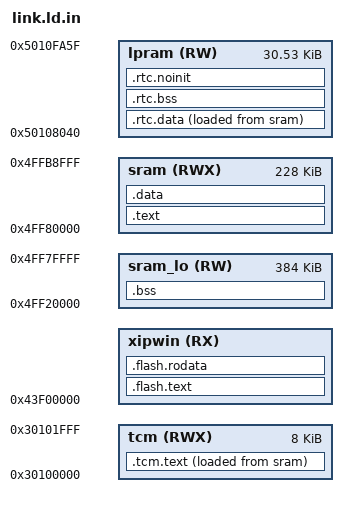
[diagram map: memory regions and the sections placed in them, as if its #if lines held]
/* ESP32-P4 (v3.x) image, run through the C preprocessor (NDF_* from the Makefile).
 * HP L2MEM 0x4FF00000-0x4FFC0000 (768 KB) is one RWX space for code and data. Its low end is the L2 cache (size set at
 * boot, up to 512 KB while the ROM runs) and the ROM's own data starts at 0x4FFBCFC0 (IDF bootloader.memory.ld.in,
 * bootloader_usable_dram_end for v3), so everything the ROM loads (code, data) goes into ROM_LO..ROM_HI. .bss and the
 * stacks go below it, into 0x4FF20000..ROM_LO, which becomes plain memory once sys_start0 has set the L2 cache to
 * 128 KB (cache.c) - before anything touches .bss or the stacks. Heap: the rest of both.
 * ponytail: TCM 0x30100000 (8 KB, zero wait) is unused; move irq_entry there (copied at boot, esptool must not see it
 * as a load segment) once the board shows L2 fetch latency in irq_latency. */
#ifndef NDF_ULP_RESERVE
#define NDF_ULP_RESERVE 0     /* bytes of LP RAM from 0x50108000 for an LP core program (ulp.h); two note words follow it */
#endif
#define XIP_VWIN 0x3F00000         /* code window: 1 MB at 0x43F00000 (flash MMU entries 1008-1023, cache.c) */
#define ROM_LO  0x4FF80000
#if NDF_BOOT_LOAD_ADDR                 /* BOOT_FAST: the ROM loads loader/loader.c, which copies the app (OTA slots); the loader keeps the top */
#define ROM_HI  0x4FFB9000               /* SOC_LOADER_BASE (soc_caps.h) */
#else
#define ROM_HI  0x4FFBCFC0
#endif
#define L2_FREE_LO 0x4FF20000      /* above a 128 KB L2 cache */
ENTRY(_start0)

MEMORY
{
    sram (RWX) : ORIGIN = ROM_LO, LENGTH = ROM_HI - ROM_LO
    sram_lo (RW) : ORIGIN = L2_FREE_LO, LENGTH = ROM_LO - L2_FREE_LO   /* not loaded by the ROM: zeroed / used after boot */
    xipwin (RX) : ORIGIN = 0x40000000 + XIP_VWIN, LENGTH = NDF_XIP_SIZE   /* code, then read-only data, in flash through the caches */
    tcm (RWX) : ORIGIN = 0x30100000, LENGTH = 0x2000   /* HP TCM: irq_entry with NDF_TCM_IRQ; not loaded by the ROM, copied at boot (sys.c) */
    lpram (RW) : ORIGIN = 0x50108000 + NDF_ULP_RESERVE + 0x40, LENGTH = 0x7A60 - NDF_ULP_RESERVE - 0x40   /* LP RAM below the loader note (0x5010FA60) and the LP ROM data (0x5010FA80); first 64 B: notes */
}

/* Same split as the S3 (esp32s3/link.ld.in): libraries never called from interrupts, flash operations or the panic
 * path. "*build*" because the P4 objects are in build-esp32p4/. */
#define XIP_LIB(S) *build*?ndf?components?lib?strtod.c.o(S) *build*?ndf?components?lib?bigint.c.o(S) *build*?ndf?components?lib?stdlib.c.o(S) *build*?ndf?components?lib?math.c.o(S) *build*?ndf?components?lib?mathf.c.o(S) \
                   *build*?ndf?components?lib?double.c.o(S) *build*?ndf?components?lib?md5.c.o(S) *build*?ndf?components?lib?crc32.c.o(S) *build*?ndf?components?lib?p256_comb.c.o(S) *build*?ndf?components?lib?ecc.c.o(S) *build*?ndf?components?lib?musl?*.c.o(S)
#define XIP_ALL(S) *build*?app?*.o(S) *build*?ndf?components?drivers?storage?*.o(S)

SECTIONS
{
#if NDF_XIP
    .flash.text : {
        _flash_text_start = ABSOLUTE(.);
        *(.flash.text .flash.text.*)                       /* FLASH_FN */
        XIP_LIB(.text .text.*)
#if NDF_XIP == 2
        XIP_ALL(.text .text.*)
#endif
        . = ALIGN(16);
        _flash_text_end = ABSOLUTE(.);
    } > xipwin

    .flash.rodata ORIGIN(xipwin) + SIZEOF(.flash.text) : {   /* same flash offset as the end of the code */
        _flash_rodata_start = ABSOLUTE(.);
        XIP_LIB(.rodata .rodata.*)
#if NDF_XIP == 2
        XIP_ALL(.rodata .rodata.*)
#endif
        . = ALIGN(16);
        _flash_rodata_end = ABSOLUTE(.);
    } > xipwin
#else
    _flash_text_start = 0; _flash_text_end = 0;
#endif

    .text : {
        KEEP(*(.iram.text .iram.text.*))            /* entry and _trap_vec (64-byte aligned) */
        *(.text .text.*)
        . = ALIGN(128);                             /* PMP granule: the code / data split of memprot.c */
        _text_end = .;
    } > sram

    .data : {
        *(.rodata .rodata.* .srodata .srodata.*)
        . = ALIGN(4);
        __global_pointer$ = . + 0x800;
        *(.data .data.* .sdata .sdata.*)
        . = ALIGN(4);
        __init_array_start = .;
        KEEP(*(SORT_BY_INIT_PRIORITY(.init_array.*) SORT_BY_INIT_PRIORITY(.ctors.*)))
        KEEP(*(.init_array .ctors))
        __init_array_end = .;
        . = ALIGN(4);
        __cmd_start = .;  KEEP(*(SORT_BY_NAME(.ndf_reg.cmd.*)))  __cmd_end = .;    /* cmd.h */
        __test_start = .; KEEP(*(SORT(.ndf_reg.test.*)))         __test_end = .;   /* unit.h, by name */
        _data_end = .;
    } > sram

    /* .tcm.text: runs in TCM, stored after .data (AT > sram), copied by sys_start0 before interrupts are enabled */
    .tcm.text : { _tcm_start = .; KEEP(*(.tcm.text .tcm.text.*)) . = ALIGN(4); _tcm_end = .; } > tcm AT > sram
    _tcm_load = LOADADDR(.tcm.text);

    .bss (NOLOAD) : ALIGN(16) {
        _bss_start = .;
        *(.sbss .sbss.* .bss .bss.* COMMON)
        . = ALIGN(4);
        _bss_end = .;
        . = ALIGN(16); _stack0_bot = .; . += NDF_STACK0_SIZE; _stack0_top = .;
        . = ALIGN(16); _stack1_bot = .; . += NDF_STACK1_SIZE; _stack1_top = .;
    } > sram_lo
    _heap_start = LOADADDR(.rtc.data) + SIZEOF(.rtc.data);
    _heap_end = ROM_HI;
    _heap2_start = _stack1_top;
    _heap2_end = ROM_LO;

    /* RTC_DATA_ATTR: lives in LP RAM (kept through deep sleep); the ROM only loads L2MEM, so the initial values travel in the
     * image after .data (AT > sram) and sys_start0 copies them on every power-up / reset except a deep-sleep wake */
    .rtc.data : { _rtc_data_start = .; *(.rtc.data .rtc.data.*) . = ALIGN(4); _rtc_data_end = .; } > lpram AT > sram
    _rtc_data_load = LOADADDR(.rtc.data);
    .rtc.bss (NOLOAD) : { _rtc_bss_start = .; *(.rtc.bss .rtc.bss.*) . = ALIGN(4); _rtc_bss_end = .; } > lpram
    .rtc.noinit (NOLOAD) : { *(.rtc.noinit .rtc.noinit.*) } > lpram

    /DISCARD/ : { *(.comment .note.* .eh_frame .riscv.attributes) }
}

ASSERT(_trap_vec % 64 == 0, "mtvec (CLIC mode) must be 64-byte aligned")
ASSERT(_heap_start <= ROM_HI, "RAM full: code + data exceed the ROM-loadable L2MEM window (0x4FF80000-0x4FFBCFC0)")
ASSERT(_stack1_top <= ROM_LO, "RAM full: .bss + stacks exceed 0x4FF20000-0x4FF80000")
ASSERT(NDF_XIP_SIZE <= 0x100000, "XIP_SIZE: the code window is 1 MB (flash MMU entries 1008-1023)")
